# TC37XPD register map
Vendor: Infineon; Series: ATVMC; File version: 100
CPU: other r0p0, little endian, MPU, FPU, vendor SysTick, 4 interrupt priority bits
Registers are 32-bit, read-write, reset 0x0 unless marked. A register's access mark holds for its fields unless they carry their own. Offsets are from the block's base; [hi:lo] are bit positions; lines under a group give offsets from that group; {n}, {i} and the like mark numbered series; 'fields as' and 'values as' point back to an identical list.

## DMA
Base 0xF0010000
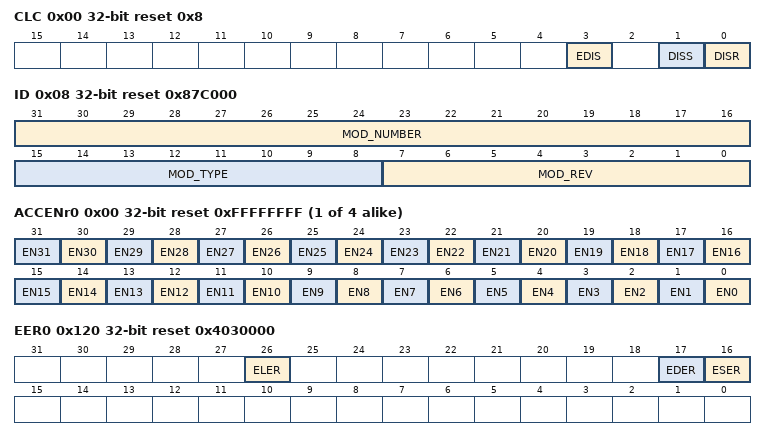
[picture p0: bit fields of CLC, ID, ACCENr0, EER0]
0x00 CLC access per field reset 0x8 — DMA Clock Control Register resetvalue={Application Reset:0x08}
  [3] EDIS rw — Sleep Mode Enable Control EDIS. Used for DMA sleep mode control.
  [1] DISS ro — Module Disable Status Bit DISS. Bit indicates the current status of the DMA
  [0] DISR rw — Module Disable Request Bit DISR. Used for enable disable control of the DMA
0x08 ID ro reset 0x87C000 (reset mask 0xFFFFFF00) — DMA Identification Register resetvalue={Application Reset:0x087C000}
  [31:16] MOD_NUMBER — Module Number Value MOD NUMBER. This bit field defines a module identification number.
  [15:8] MOD_TYPE — Module Type MOD TYPE. The bit field is set to C0 H which defines the module as a 32 bit module.
  [7:0] MOD_REV — Module Revision Number MOD REV. This bit field defines the module revision number. See DMA Design Specification for MOD REV value.
{0x40+8i} ACCEN[{i}] (i=0..3) group
  0x00 ACCENr0 reset 0xFFFFFFFF — RP 0 Access Enable Register 0 resetvalue={Application Reset:0x0FFFFFFFF}
    [n] EN{n} (n=0..31) — Access Enable for Master TAG ID q ENq. This bit enables write access to the module kernel addresses for transactions with the Master TAG ID q
0x120 EER0 reset 0x4030000 — ME 1 Enable Error Register resetvalue={Application Reset:0x4030000}
  [26] ELER — Enable ME DMA Linked List Error ELER. This bit enables the generation of a ME DMA Linked List error interrupt.
  [17] EDER — Enable ME Destination Error EDER. This bit enables the generation of a ME destination error interrupt.
  [16] ESER — Enable ME Source Error ESER. This bit enables the generation of a ME source error interrupt.
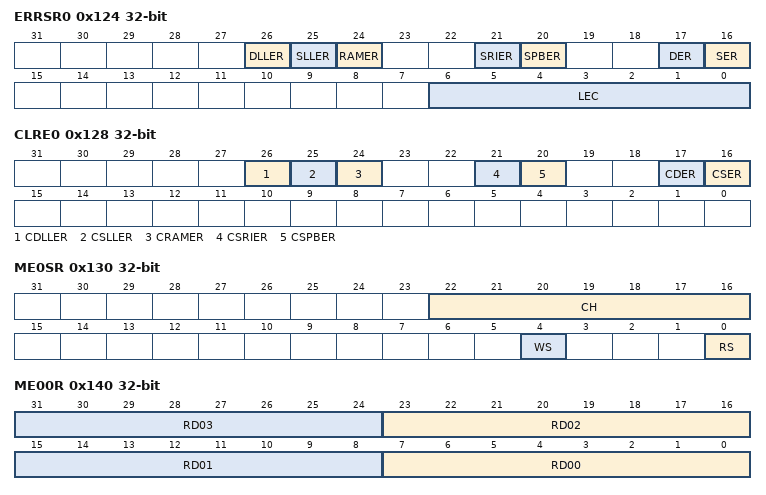
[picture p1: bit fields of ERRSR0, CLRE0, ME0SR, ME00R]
0x124 ERRSR0 ro — ME 1 Error Status Register resetvalue={Application Reset:0x0}
  [26] DLLER — ME DMA Linked List Error DLLER. This bit is set when a ME error occurred during a DMALL ACCLL SAFLL or CONLL operation when a new TCS is loaded from anywhere in memory to overwrite the current TCS stored in the DMARAM.
  [25] SLLER — ME Safe Linked List Error SLLER. This bit is set when a ME error occurred during the comparison of a SDCRC checksums during a safe linked list.
  [24] RAMER — ME RAM Error RAMER. This bit is set whenever a ME error occurred during the loading of a TCS from the DMARAM to the ME channel registers.
  [21] SRIER — ME SRI Bus Error SRIER. This bit is set when a ME DMA Move that has been started by the DMA SRI master interface leads to an error on the SRI 160 Bus.
  [20] SPBER — ME SPB Bus Error SPBER. This bit is set when a ME DMA Move that has been started by the DMA SPB master interface leads to an error on the SPB 160 Bus.
  [17] DER — ME Destination Error DER. This bit is set whenever a ME error occurred during a destination write move of a DMA transfer or a request could not been serviced due to the access protection.
  [16] SER — ME Source Error SER. This bit is set whenever a ME error occurred during a source read move of a DMA transfer or a request could not been serviced due to the access protection.
  [6:0] LEC — ME Last Error Channel LEC. This bit field indicates the DMA channel number of the last DMA channel of ME generating an error i.e. RAM error DMA ERRSRm.RAMER Safe Linked List error DMA ERRSRm.SLLER DMA Linked List error DMA ERRSRm.DLLER and all on 160 chip 160 bus errors.
0x128 CLRE0 wo — ME 1 Clear Error Register resetvalue={Application Reset:0x0}
  [26] CDLLER — Clear DLL Error CDLLER
  [25] CSLLER — Clear SLL Error CSLLER
  [24] CRAMER — Clear RAM Error CRAMER
  [21] CSRIER — Clear SRI Error CSRIER
  [20] CSPBER — Clear SPB Error CSPBER
  [17] CDER — Clear ME Destination Error CDER
  [16] CSER — Clear ME Source Error CSER
0x130 ME0SR ro — ME 1 Status Register resetvalue={Application Reset:0x0}
  [22:16] CH — ME Active Channel CH. Indicates the number of the DMA Channel currently processed by the ME.
  [4] WS — ME Write Status WS
  [0] RS — ME Read Status RS
0x140 ME00R ro — ME 1 Read Register 0 resetvalue={Application Reset:0x0}
  [8n+7:8n] RD{n:02} (n=0..3) — DMA Read Move Data Byte RD{n:02}
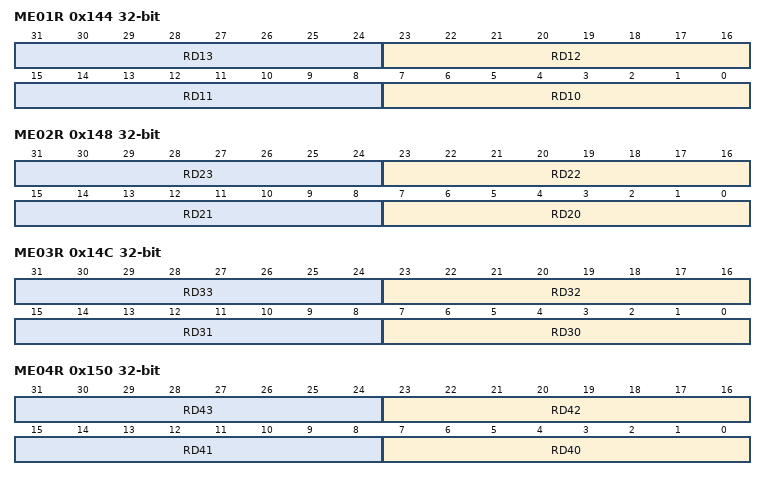
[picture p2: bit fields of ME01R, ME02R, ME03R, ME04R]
0x144 ME01R ro — ME 1 Read Register 1 resetvalue={Application Reset:0x0}
  [8n-73:8n-80] RD{n} (n=10..13) — DMA Read Move Data Byte RD{n}
0x148 ME02R ro — ME 1 Read Register 2 resetvalue={Application Reset:0x0}
  [8n-153:8n-160] RD{n} (n=20..23) — DMA Read Move Data Byte RD{n}
0x14C ME03R ro — ME 1 Read Register 3 resetvalue={Application Reset:0x0}
  [8n-233:8n-240] RD{n} (n=30..33) — DMA Read Move Data Byte RD{n}
0x150 ME04R ro — ME 1 Read Register 4 resetvalue={Application Reset:0x0}
  [8n-313:8n-320] RD{n} (n=40..43) — DMA Read Move Data Byte RD{n}
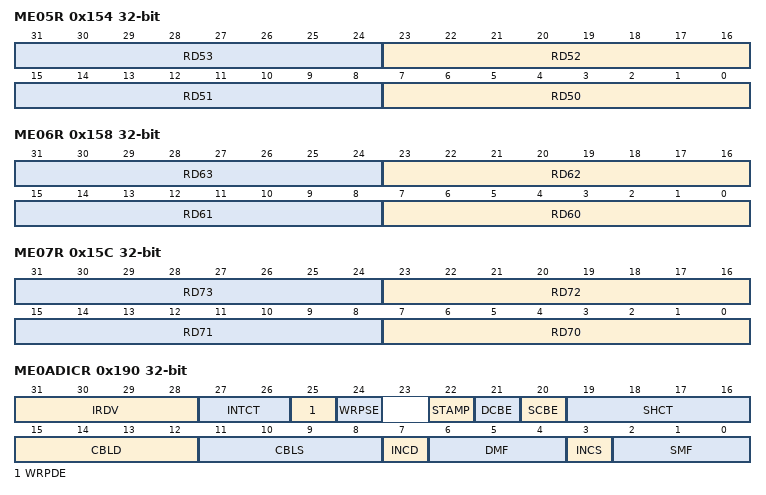
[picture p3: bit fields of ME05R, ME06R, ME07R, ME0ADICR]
0x154 ME05R ro — ME 1 Read Register 5 resetvalue={Application Reset:0x0}
  [8n-393:8n-400] RD{n} (n=50..53) — DMA Read Move Data Byte RD{n}
0x158 ME06R ro — ME 1 Read Register 6 resetvalue={Application Reset:0x0}
  [8n-473:8n-480] RD{n} (n=60..63) — DMA Read Move Data Byte RD{n}
0x15C ME07R ro — ME 1 Read Register 7 resetvalue={Application Reset:0x0}
  [8n-553:8n-560] RD{n} (n=70..73) — DMA Read Move Data Byte RD{n}
0x180 ME0RDCRC ro — ME 1 Channel Read Data CRC Register resetvalue={Application Reset:0x0}
  [31:0] RDCRC — Read Data CRC RDCRC. Active DMA channel read data CRC32 ethernet polynomial checksum.
0x184 ME0SDCRC ro — ME 1 Channel Source and Destination Address CRC Register resetvalue={Application Reset:0x0}
  [31:0] SDCRC — Source and Destination Address CRC SDCRC. Active DMA channel source and destination address CRC32 ethernet polynomial checksum.
0x188 ME0SADR ro — ME 1 Channel Source Address Register resetvalue={Application Reset:0x0}
  [31:0] SADR — Source Address SADR. Active DMA channel 32 bit source address used for DMA read moves.
0x18C ME0DADR ro — ME 1 Channel Destination Address Register resetvalue={Application Reset:0x0}
  [31:0] DADR — Destination Address DADR. Active DMA channel 32 bit destination address used for DMA write moves.
0x190 ME0ADICR ro — ME 1 Channel Address and Interrupt Control Register resetvalue={Application Reset:0x0}
  [31:28] IRDV — Interrupt Raise Detect Value IRDV. Active DMA channel control of the Threshold Limit of of DMA channel CHSR.TCOUNT for triggering a channel interrupt service request.
  [27:26] INTCT — Interrupt Control INTCT. Active DMA channel interrupt service request control.
  [25] WRPDE — Wrap Destination Enable WRPDE. Active DMA channel destination buffer interrupt trigger enable disable.
  [24] WRPSE — Wrap Source Enable WRPSE. Active DMA channel source buffer interrupt trigger enable disable.
  [22] STAMP — Time Stamp STAMP. Active DMA channel control to enable the appendage of a timestamp after the end of the last DMA Move during a DMA transaction.
  [21] DCBE — Destination Circular Buffer Enable DCBE. Active DMA channel circular destination buffer enable disable.
  [20] SCBE — Source Circular Buffer Enable SCBE. Active DMA channel circular source buffer enable disable.
  [19:16] SHCT — Shadow Control SHCT. Active DMA channel control of shadow address register function.
  [15:12] CBLD — Circular Buffer Length Destination CBLD. Active DMA channel circular destination buffer control.
  [11:8] CBLS — Circular Buffer Length Source CBLS. Active DMA channel circular source buffer control.
  [7] INCD — Increment of Destination Address INCD. Active DMA channel increment of destination address control.
  [6:4] DMF — Destination Address Modification Factor DMF. Active DMA channel destination address modification factor.
  [3] INCS — Increment of Source Address INCS. Active DMA channel increment of source address control.
  [2:0] SMF — Source Address Modification Factor SMF. Active DMA channel source address modification factor.
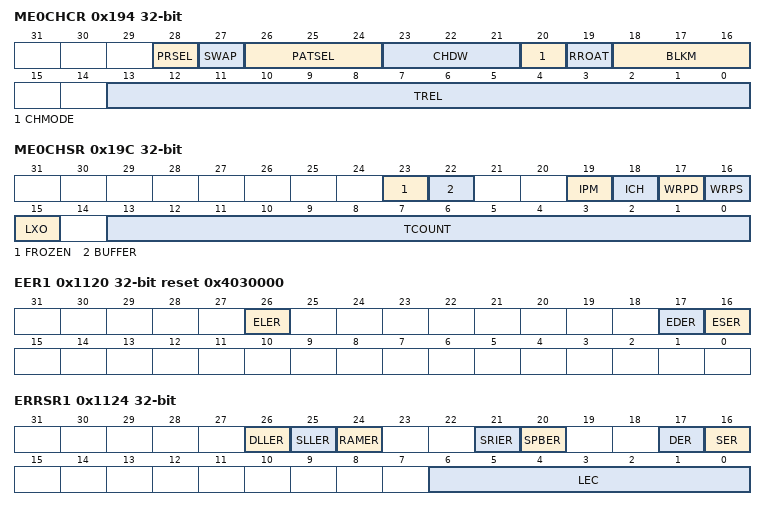
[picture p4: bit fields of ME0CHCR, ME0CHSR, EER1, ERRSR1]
0x194 ME0CHCR ro — ME 1 Channel Control Register resetvalue={Application Reset:0x0}
  [28] PRSEL — Peripheral Request Select PRSEL. Active DMA channel Peripheral Request Select.
  [27] SWAP — Swap Data CRC byte order SWAP. Active DMA channel swap data CRC byte order.
  [26:24] PATSEL — Pattern Select PATSEL. Active DMA channel Pattern Select control.
  [23:21] CHDW — Channel Data Width CHDW. Active DMA channel DMA move Channel Data Width.
  [20] CHMODE — Channel Operation Mode CHMODE. Active DMA channel Channel Operation Mode.
  [19] RROAT — Reset Request Only After Transaction RROAT. Active DMA channel Reset Request Only After Transaction.
  [18:16] BLKM — Block Mode BLKM. Active DMA channel Block Mode.
  [13:0] TREL — Transfer Reload Value TREL. Active DMA channel Transfer Reload Value.
0x198 ME0SHADR ro — ME 1 Channel Shadow Address Register resetvalue={Application Reset:0x0}
  [31:0] SHADR — Shadowed Address SHADR. This bit field holds the 32 bit shadow address of the active DMA channel. The function of the shadow address is set by the shadow control settings.
0x19C ME0CHSR ro — ME 1 Channel Status Register resetvalue={Application Reset:0x0}
  [23] FROZEN — DMA Double Buffering Frozen Buffer FROZEN. Active DMA channel DMA Double Buffering Frozen Buffer status bit.
  [22] BUFFER — DMA Double Buffering Active Buffer BUFFER. Active DMA channel DMA Double Buffering Active Buffer status bit.
  [19] IPM — Pattern Detection from Channel IPM. Active DMA channel detection of pattern match interrupt service request.
  [18] ICH — Interrupt from Channel ICH. Active DMA channel detection of channel interrupt service request.
  [17] WRPD — Wrap Destination Buffer WRPD. Active DMA channel Wrap Destination Buffer status bit.
  [16] WRPS — Wrap Source Buffer WRPS. Active DMA channel Wrap Source Buffer status bit.
  [15] LXO — Old Value of Pattern Detection LXO. Active DMA channel compare result of a pattern compare operation when 8 bit or 16 bit data width is selected.
  [13:0] TCOUNT — Transfer Count Status TCOUNT. Active DMA channel count of the number of DMA transfers. TCOUNT is loaded with the DMA channel value of CHCFGR.TREL when TSR.CH becomes set and TCOUNT 160 160 0 . After each DMA transfer TCOUNT is decremented by 1.
0x1120 EER1 reset 0x4030000 — ME 1 Enable Error Register resetvalue={Application Reset:0x4030000}
  fields as EER0
0x1124 ERRSR1 ro — ME 1 Error Status Register resetvalue={Application Reset:0x0}
  fields as ERRSR0
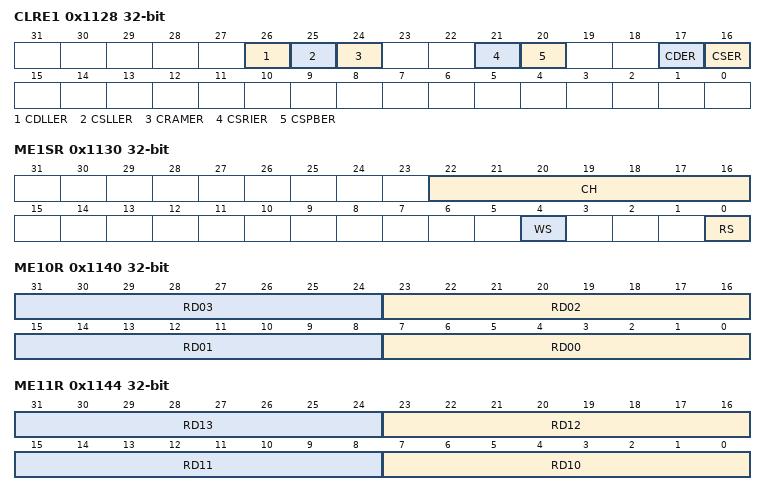
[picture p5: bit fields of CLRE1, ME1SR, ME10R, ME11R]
0x1128 CLRE1 wo — ME 1 Clear Error Register resetvalue={Application Reset:0x0}
  fields as CLRE0
0x1130 ME1SR ro — ME 1 Status Register resetvalue={Application Reset:0x0}
  fields as ME0SR
0x1140 ME10R ro — ME 1 Read Register 0 resetvalue={Application Reset:0x0}
  [8n+7:8n] RD{n:02} (n=0..3) — DMA Read Move Data Byte RD{n:02}
0x1144 ME11R ro — ME 1 Read Register 1 resetvalue={Application Reset:0x0}
  [8n-73:8n-80] RD{n} (n=10..13) — DMA Read Move Data Byte RD{n}
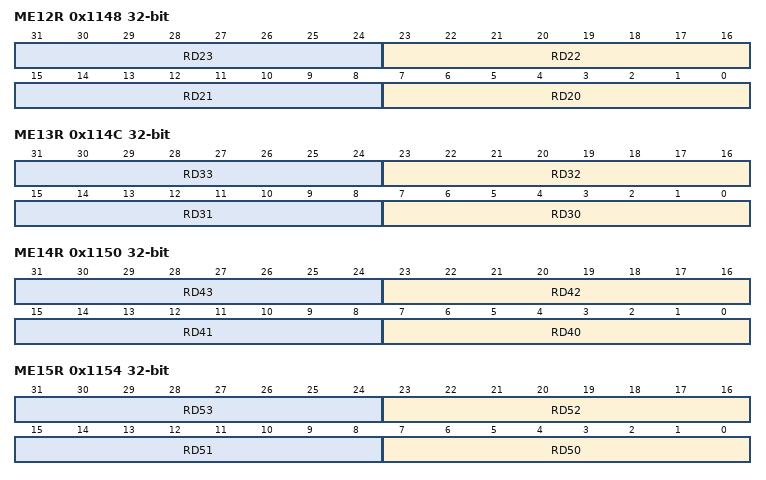
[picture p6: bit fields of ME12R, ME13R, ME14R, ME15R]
0x1148 ME12R ro — ME 1 Read Register 2 resetvalue={Application Reset:0x0}
  [8n-153:8n-160] RD{n} (n=20..23) — DMA Read Move Data Byte RD{n}
0x114C ME13R ro — ME 1 Read Register 3 resetvalue={Application Reset:0x0}
  [8n-233:8n-240] RD{n} (n=30..33) — DMA Read Move Data Byte RD{n}
0x1150 ME14R ro — ME 1 Read Register 4 resetvalue={Application Reset:0x0}
  [8n-313:8n-320] RD{n} (n=40..43) — DMA Read Move Data Byte RD{n}
0x1154 ME15R ro — ME 1 Read Register 5 resetvalue={Application Reset:0x0}
  [8n-393:8n-400] RD{n} (n=50..53) — DMA Read Move Data Byte RD{n}
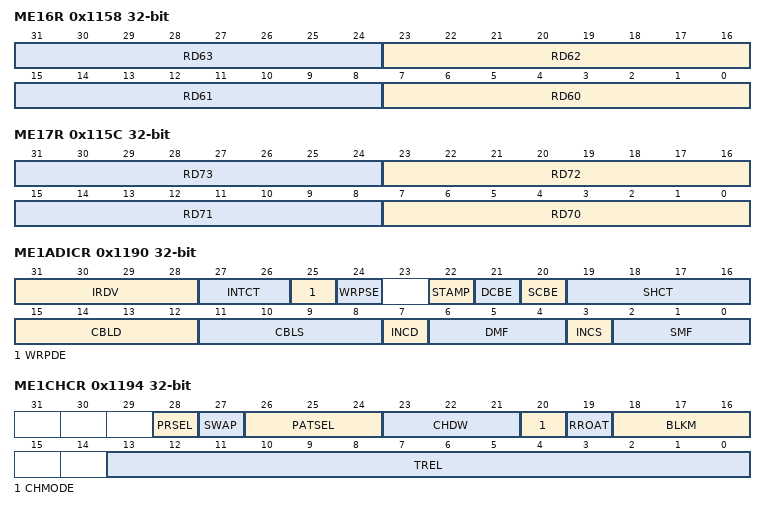
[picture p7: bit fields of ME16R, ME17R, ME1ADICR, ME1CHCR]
0x1158 ME16R ro — ME 1 Read Register 6 resetvalue={Application Reset:0x0}
  [8n-473:8n-480] RD{n} (n=60..63) — DMA Read Move Data Byte RD{n}
0x115C ME17R ro — ME 1 Read Register 7 resetvalue={Application Reset:0x0}
  [8n-553:8n-560] RD{n} (n=70..73) — DMA Read Move Data Byte RD{n}
0x1180 ME1RDCRC ro — ME 1 Channel Read Data CRC Register resetvalue={Application Reset:0x0}
  fields as ME0RDCRC
0x1184 ME1SDCRC ro — ME 1 Channel Source and Destination Address CRC Register resetvalue={Application Reset:0x0}
  fields as ME0SDCRC
0x1188 ME1SADR ro — ME 1 Channel Source Address Register resetvalue={Application Reset:0x0}
  fields as ME0SADR
0x118C ME1DADR ro — ME 1 Channel Destination Address Register resetvalue={Application Reset:0x0}
  fields as ME0DADR
0x1190 ME1ADICR ro — ME 1 Channel Address and Interrupt Control Register resetvalue={Application Reset:0x0}
  fields as ME0ADICR
0x1194 ME1CHCR ro — ME 1 Channel Control Register resetvalue={Application Reset:0x0}
  fields as ME0CHCR
0x1198 ME1SHADR ro — ME 1 Channel Shadow Address Register resetvalue={Application Reset:0x0}
  fields as ME0SHADR
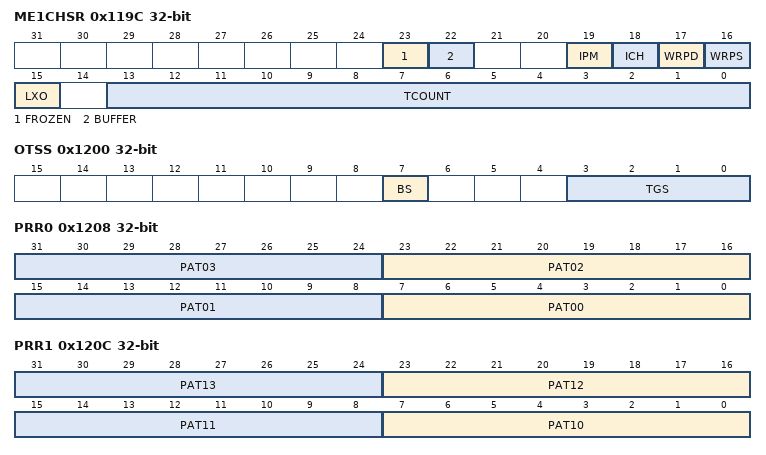
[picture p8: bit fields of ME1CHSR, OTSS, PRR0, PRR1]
0x119C ME1CHSR ro — ME 1 Channel Status Register resetvalue={Application Reset:0x0}
  fields as ME0CHSR
0x1200 OTSS — DMA OCDS Trigger Set Select resetvalue={PowerOn Reset:0x0,Debug Reset:0x0}
  [7] BS — OTGB0 or OTGB1 Bus Select BS
  [3:0] TGS — Trigger Set for OTGB0 or OTGB1 TGS
0x1208 PRR0 — DMA Pattern Read Register 0 resetvalue={Application Reset:0x0}
  [8n+7:8n] PAT{n:02} (n=0..3) — Pattern Data Byte PAT{n:02}
0x120C PRR1 — DMA Pattern Read Register 1 resetvalue={Application Reset:0x0}
  [8n-73:8n-80] PAT{n} (n=10..13) — Pattern Data Byte PAT{n}
0x1210 TIME ro — DMA Time Register resetvalue={Application Reset:0x0}
  [31:0] COUNT — Timestamp Count COUNT. The count value used during the appendage of DMA timestamps.
{0x1300+4i} MODEr[{i}] (i=0..3) reset 0x1 — RP 0 Mode Register resetvalue={Application Reset:0x1}
  [0] MODE — Resource Partition Supervisor Mode MODE
{0x1320+4i} ERRINTRr[{i}] (i=0..3) wo — RP 0 Error Interrupt Set Register resetvalue={Application Reset:0x0}
  [0] SIT — Set Error Interrupt Service Request SIT. Reading this bit returns a 0.
{0x1800+4i} HRRc[{i}] (i=0..127) — DMA Channel 000 Resource Partition Register resetvalue={Application Reset:0x0}
  [1:0] HRP — DMA Channel Resource Partition HRP
{0x1A00+4i} SUSENRc[{i}] (i=0..127) — DMA Channel 000 Suspend Enable Register resetvalue={PowerOn Reset:0x0,Debug Reset:0x0}
  [0] SUSEN — Channel Suspend Enable for DMA Channel SUSEN. Enables the DMA channel suspend capability. Channel suspend mode shall be terminated when SUSEN is written with 0.
{0x1C00+4i} SUSACRc[{i}] (i=0..127) ro — DMA Channel 000 Suspend Acknowledge Register resetvalue={PowerOn Reset:0x0,Debug Reset:0x0}
  [0] SUSAC — DMA Channel Suspend State or Frozen State Active for DMA Channel SUSAC. Status bit indicates whether or not a DMA channel is in channel suspend state or in the frozen state.
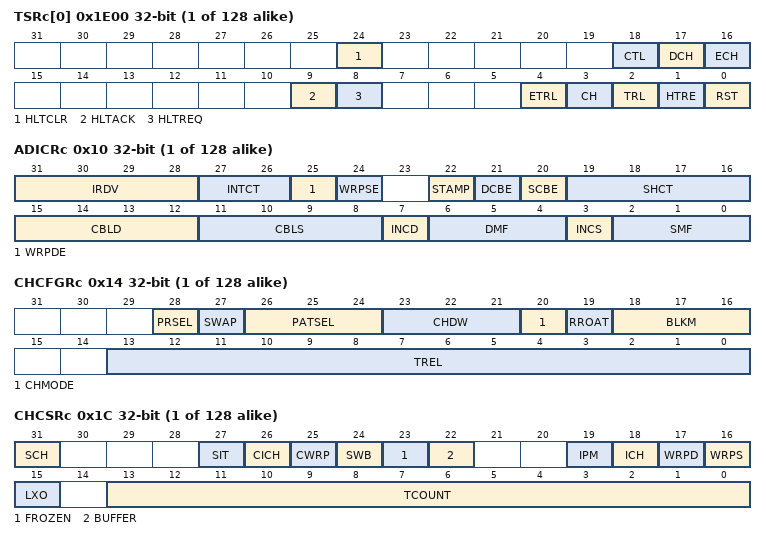
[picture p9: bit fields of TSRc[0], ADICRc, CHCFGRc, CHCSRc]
{0x1E00+4i} TSRc[{i}] (i=0..127) access per field — DMA Channel 000 Transaction State Register resetvalue={Application Reset:0x0}
  [24] HLTCLR wo — Clear DMA Channel Halt Request and Acknowledge HLTCLR. Reading this bit returns a 0.
  [18] CTL wo — Clear DMA Channel Transaction Transfer Request Lost CTL. Software clear of the DMA channel TRL status flag. Reading this bit returns a 0.
  [17] DCH wo — Disable DMA Channel Hardware Transaction Request DCH. See Functional Description. Reading this bit returns a 0.
  [16] ECH wo — Enable DMA Channel Hardware Transaction Request ECH. See Functional Description. Reading this bit returns a 0.
  [9] HLTACK ro — DMA Channel Halt Acknowledge HLTACK
  [8] HLTREQ rw — DMA Channel Halt Request HLTREQ. The DMA channel halt request bit is set by software writing DMA channel TSR.HLTREQ 1 and cleared by software writing DMA channel TSR.HLTCLR 1 .
  [4] ETRL rw — Enable DMA Channel Transaction Transfer Request Lost Interrupt ETRL. DMA channel control bit to enable the generation of an error interrupt service request when DMA channel TSR.TRL is set.
  [3] CH ro — DMA Channel Transaction Request State CH. CH is reset when a pattern match is detected.
  [2] TRL ro — DMA Channel Transaction Transfer Request Lost TRL. This bit is reset by software clearing TRL writing DMA channel TSR.CTL 1 or resetting the DMA channel writing DMA channel TSR.RST 160 160 1 .
  [1] HTRE ro — DMA Channel Hardware Request Enable HTRE . See Functional Description for enable and disable. When a DMA channel is configured for single mode HTRE is reset when ME CHSR.TCOUNT is decremented and ME CHSR.TCOUNT 0. When a DMA channel error is reported or a pattern match is detected DMA channel HTRE is reset.
  [0] RST rw — DMA Channel Reset RST. The DMA channel reset bit is set by software DMA channel TSR.RST 1 and cleared by hardware when the DMA channel has been reset.
{0x2000+0x20*i} CH[{i}] (i=0..127) group
  0x00 RDCRCRc — DMARAM Channel 000 Read Data CRC Register resetvalue={Application Reset:0x0}
    [31:0] RDCRC — Read Data CRC RDCRC. Checksum calculated for DMA read move data.
  0x04 SDCRCRc — DMARAM Channel 000 Source and Destination Address CRC Register resetvalue={Application Reset:0x0}
    [31:0] SDCRC — Source and Destination Address CRC SDCRC. Checksum calculated for DMA move source and destination addresses.
  0x08 SADRc — DMARAM Channel 000 Source Address Register resetvalue={Application Reset:0x0}
    [31:0] SADR — Source Address SADR. 32 bit source address.
  0x0C DADRc — DMARAM Channel 000 Destination Address Register resetvalue={Application Reset:0x0}
    [31:0] DADR — Destination Address DADR. 32 bit destination address.
  0x10 ADICRc — DMARAM Channel 000 Address and Interrupt Control Register resetvalue={Application Reset:0x0}
    [31:28] IRDV — Interrupt Raise Detect Value IRDV. DMA channel TCS interrupt threshold value defines the Threshold Limit of CHSR.TCOUNT for which a channel interrupt trigger will be raised.
    [27:26] INTCT — Interrupt Control INTCT. DMA channel TCS interrupt control. If DMA channel CHCFGR.PRSEL 1 B for the next lower priority channel then the channel transfer trigger interrupt is disabled.
    [25] WRPDE — Wrap Destination Enable WRPDE. DMA channel TCS destination buffer interrupt trigger enable disable.
    [24] WRPSE — Wrap Source Enable WRPSE. DMA channel TCS source buffer interrupt trigger enable disable.
    [22] STAMP — Time Stamp STAMP. DMA channel TCS control bit to enable the appendage of a timestamp after the end of the last DMA Move during a DMA transaction.
    [21] DCBE — Destination Circular Buffer Enable DCBE. DMA channel TCS destination circular buffer enable.
    [20] SCBE — Source Circular Buffer Enable SCBE. DMA channel TCS source circular buffer enable.
    [19:16] SHCT — Shadow Control SHCT. DMA channel TCS shadow control determines the function of the shadow address register.
    [15:12] CBLD — Circular Buffer Length Destination CBLD. DMA channel TCS circular buffer destination address update control bit determines which part of the 32 bit destination address register remains unchanged and is not updated after a DMA move operation. CBLD determines the size of the circular destination buffer.
    [11:8] CBLS — Circular Buffer Length Source CBLS. DMA channel TCS circular buffer source address update control bit determines which part of the 32 bit source address register remains unchanged and is not updated after a DMA move operation. CBLS determines the size of the circular source buffer.
    [7] INCD — Increment of Destination Address INCD. DMA channel TCS control bit to determine if the address offset selected by DMF will be added to or subtracted from the destination address after each DMA move. If DCBE 1 B and CBLD 160 160 0000 B the destination address is not modified.
    [6:4] DMF — Destination Address Modification Factor DMF. DMA channel TCS 32 bit destination address modification factor and the channel data width CHDW determines an address offset value by which the destination address is modified after each DMA move. If DCBE 1 B and CBLD 160 160 0000 B then the destination address is not modified.
    [3] INCS — Increment of Source Address INCS. DMA channel TCS control bit to determine if the address offset selected by SMF will be added to or subtracted from the source address after each DMA move. If SCBE 1 B and CBLS 160 160 0000 B then the source address is not modified.
    [2:0] SMF — Source Address Modification Factor SMF. DMA channel TCS 32 bit source address modification factor and the channel data width CHDW determines an address offset value by which the source address is modified after each DMA move. If SCBE 1 B and CBLS 160 160 0000 B then the source address is not modified.
  0x14 CHCFGRc — DMARAM Channel 000 Configuration Register resetvalue={Application Reset:0x0}
    [28] PRSEL — Peripheral Request Select PRSEL. DMA channel TCS control bit field to select the source of a DMA request.
    [27] SWAP — Swap Data CRC Byte Order SWAP. DMA channel TCS swap data CRC byte order.
    [26:24] PATSEL — Pattern Select PATSEL. DMA channel TCS bit field to select the pattern detection operation see Functional Description . If PATSEL 1 0 is not equal to 00 B then a ME pattern detection operation defined by the channel data width CHDW will be performed. PATSEL 2 selects the pattern read register. If a pattern match is detected then a DMA channel interrupt shall be triggered.
    [23:21] CHDW — Channel Data Width CHDW. DMA channel TCS data width for DMA read moves and DMA write moves.
    [20] CHMODE — Channel Operation Mode CHMODE. DMA channel TCS control to determine TSR.HTRE reset condition.
      0=Single_Mode0 (0 Single Mode is selected for DMA channel. After a DMA transaction DMA channel is disabled for further hardware requests TSR.HTRE is reset by hardware TSR.HTRE must be set again by software for starting a new transaction.); 1=Continuous_Mode1 (1 Continuous Mode is selected for DMA channel. After a DMA transaction bit TSR.HTRE remains set.)
    [19] RROAT — Reset Request Only After Transaction RROAT. DMA channel control bit to determine if the DMA request state flag DMA channel TSR.CH is reset after each DMA transfer.
    [18:16] BLKM — Block Mode BLKM. Defines the number of DMA moves executed during one DMA transfer.
    [13:0] TREL — Transfer Reload Value TREL. DMA channel TCS transfer reload value to control the number of DMA transfers in a DMA transaction. The 14 bit transfer count value is loaded into ME CHSR.TCOUNT at the start of a DMA transaction when TSR.CH becomes set and CHSR.TCOUNT 160 160 0 . A write to CHCFGR.TREL during a running DMA transaction has no influence on the running DMA transaction. If CHCFGR.TREL 160 160 0 or if CHCFGR.TREL 160 160 1 then ME CHSR.TCOUNT will be loaded with 1 when a new DMA transaction is started at least one DMA transfer must be executed per DMA transaction .
  0x18 SHADRc — DMARAM Channel 000 Shadow Address Register resetvalue={Application Reset:0x0}
    [31:0] SHADR — Shadowed Address SHADR. 32 bit shadow address.
  0x1C CHCSRc access per field — DMARAM Channel 000 Control and Status Register resetvalue={Application Reset:0x0}
    [31] SCH wo — Set Transaction Request SCH. Reading this bit returns a 0.
    [27] SIT wo — Set Interrupt Trigger for DMA Channel SIT. Reading this bit returns a 0. If a DMALL ACCLL SAFLL or CONLL operation is configured then SIT must be 0 B .
    [26] CICH wo — Clear Interrupt for DMA Channel CICH. Software clear of the DMA channel flags stored at CHCSR.ICH and CHCSR.IPM. If the DMA channel is active in a ME then clear ME bit fields CHSR.ICH and CHSR.IPM. Reading this bit returns a 0.
    [25] CWRP wo — Clear Wrap Buffer Interrupt CWRP. Software clear of the DMA channel source and destination wrap buffer flags stored at CHCSR.WRPS and CHCSR.WRPD. If the DMA channel is active in a ME then clear ME bit fields CHSR.WRPS and CHSR.WRPD. Reading this bit returns a 0.
    [24] SWB wo — DMA Double Buffering Switch Buffer SWB. When DMA double buffering is configured the control bit is used to re direct data from one buffer to the other buffer. If a DMALL ACCLL SAFLL or CONLL operation is configured then SWB shall be 0 B .
    [23] FROZEN rw — DMA Double Buffering Frozen Buffer FROZEN. If a DMA channel is configured for double buffering operation the FROZEN bit indicates that one of the buffers is frozen and available for processing by a cyclic software task. FROZEN bit shall only be set by the DMA and shall only be cleared by software.
    [22] BUFFER ro — DMA Double Buffering Active Buffer BUFFER. During a DMA double buffering operation the status bit indicates which buffer is read or filled.
    [19] IPM ro — Pattern Detection from Channel IPM. Status bit indicates that a pattern match has been detected for the DMA channel when pattern detection is enabled. This bit is reset by software DMA channel CHCSR.CICH 1 B or DMA channel reset TSR.RST 1 B .
    [18] ICH ro — Interrupt from Channel ICH. As soon as ME CHSR.TCOUNT decrements if ADICR.INTCT 0 0 and CHSR.COUNT IRDV then ME CHSR.ICH is set else ME CHSR.ICH is set for each decrement of CSR.TCOUNT. Bit is reset by software DMA channel CHCSR.CICH 1 B or by a DMA channel reset TSR.RST 1 B .
    [17] WRPD ro — Wrap Destination Buffer WRPD. Status bit indicates that a DMA channel has reached a wrap destination buffer boundary. Bit is reset by software DMA channel CHCSR.CWRP 1 B or DMA channel reset TSR.RST 1 B .
    [16] WRPS ro — Wrap Source Buffer WRPS. Status bit indicates that a DMA channel has reached a wrap source buffer boundary. Bit is reset by software DMA channel CHCSR.CWRP 1 B or DMA channel reset TSR.RST 1 B .
    [15] LXO ro — Old Value of Pattern Detection LXO. DMA channel status bit to store the result of a pattern detection operation when 8 bit or 16 bit data width is selected.
    [13:0] TCOUNT ro — Transfer Count TCOUNT. DMA channel status transfer count updated after DMARAM write back.
